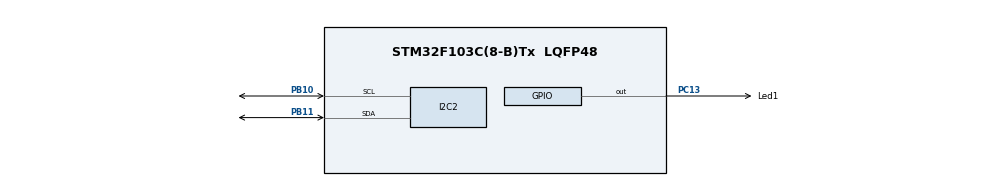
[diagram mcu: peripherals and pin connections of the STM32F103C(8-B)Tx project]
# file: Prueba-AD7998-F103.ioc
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Mcu.Family=STM32F1
Mcu.Name=STM32F103C(8-B)Tx
Mcu.Package=LQFP48
NVIC.I2C2_ER_IRQn=true\:0\:0\:false\:false\:true\:true\:true\:true
NVIC.I2C2_EV_IRQn=true\:0\:0\:false\:false\:true\:true\:true\:true
NVIC.PriorityGroup=NVIC_PRIORITYGROUP_4
PA13.Mode=Serial_Wire
PA13.Signal=SYS_JTMS-SWDIO
PA14.Mode=Serial_Wire
PA14.Signal=SYS_JTCK-SWCLK
PB10.Mode=I2C
PB10.Signal=I2C2_SCL
PB11.Mode=I2C
PB11.Signal=I2C2_SDA
PC13-TAMPER-RTC.GPIO_Label=Led1
PC13-TAMPER-RTC.Signal=GPIO_Output
PD0-OSC_IN.Mode=HSE-External-Oscillator
PD0-OSC_IN.Signal=RCC_OSC_IN
PD1-OSC_OUT.Mode=HSE-External-Oscillator
PD1-OSC_OUT.Signal=RCC_OSC_OUT
ProjectManager.HeapSize=0x200
ProjectManager.StackSize=0x400
ProjectManager.TargetToolchain=STM32CubeIDE
RCC.APB1Freq_Value=8000000
RCC.APB2Freq_Value=8000000
board=custom

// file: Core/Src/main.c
/* USER CODE BEGIN Header */
/**
  ******************************************************************************
  * @file           : main.c
  * @brief          : Main program body
  ******************************************************************************
  * @attention
  *
  * Copyright (c) 2025 STMicroelectronics.
  * All rights reserved.
  *
  * This software is licensed under terms that can be found in the LICENSE file
  * in the root directory of this software component.
  * If no LICENSE file comes with this software, it is provided AS-IS.
  *
  ******************************************************************************
  */
/* USER CODE END Header */
#include "main.h"

/* USER CODE BEGIN Includes */
#include "stdio.h"
#include "string.h"
#include "stdlib.h"

/* USER CODE END Includes */

/* USER CODE BEGIN PD */
#define AD7998_1_ADDR  (0x24 << 1)  // Dirección del primer AD7998
/* USER CODE END PD */

I2C_HandleTypeDef hi2c2;

/* USER CODE BEGIN PV */
uint8_t flag=0;
uint16_t ch_values [8]={0};
char msg[64];
/* USER CODE END PV */

void SystemClock_Config(void);
static void MX_GPIO_Init(void);
static void MX_I2C2_Init(void);

/* USER CODE BEGIN 0 */
//-------------------------------------------------------------------------------------------[Función para detectar dispositivos]

void I2C_Scan(I2C_HandleTypeDef *hi2c)
{
    for (uint8_t i = 1; i < 128; i++)
    {
        if (HAL_I2C_IsDeviceReady(hi2c, (i << 1), 1, HAL_MAX_DELAY) == HAL_OK)
        {
            sprintf(msg, "Device found at 0x%X\r\n", i);
        }
    }
}

//-------------------------------------------------------------------------------------------[Función para configurar canales]
HAL_StatusTypeDef AD7998_ConfigureAllChannels(uint8_t dev_addr)
{
    uint8_t config_payload[3];

    // 1. Primer byte: Puntero al Registro de Configuración del Ciclo de Conversión (0x02)
    config_payload[0] = 0x02;

    // 2. Segundo byte: MSB de los canales a habilitar (D15-D8). 0x0F -> 0000 1111
    config_payload[1] = 0x0F;

    // 3. Tercer byte: LSB de los canales a habilitar (D7-D0). 0xF0 -> 1111 0000
    config_payload[2] = 0xF0;

    // Juntos, 0x0FF0 habilita los canales del 1 al 8.
    // Transmitimos el paquete de 3 bytes.
    return HAL_I2C_Master_Transmit(&hi2c2, dev_addr, config_payload, 3, HAL_MAX_DELAY);
}

//-------------------------------------------------------------------------------------------[Función para leer los 8 canales de un AD7998]
uint16_t AD7998_ReadChannel(uint8_t dev_addr, uint8_t channel)
{
    HAL_StatusTypeDef ret;
    uint8_t config;
    uint8_t data[2];
    uint16_t value = 0;

    // Canal 1–8 → bits 6:4 del byte de configuración
    if (channel < 1 || channel > 8)
        return 0xFFFF; // error de canal inválido

    config = 0x80 | ((channel - 1) << 4); // bit7=1, selecciona canal.... 0x40 es para canal 7

    // Escribir el byte de configuración
    ret = HAL_I2C_Master_Transmit(&hi2c2, dev_addr, &config, 1, HAL_MAX_DELAY);
    if (ret != HAL_OK)
        return 0xFFFE; // error de transmisión

    // Pequeño retardo para que complete la conversión
    HAL_Delay(10);

    // Leer 2 bytes (MSB + LSB)
    ret = HAL_I2C_Master_Receive(&hi2c2, dev_addr, data, 2, HAL_MAX_DELAY);
    if (ret != HAL_OK)
        return 0xFFFD; // error de lectura

    // Combinar los dos bytes (12 bits válidos)
    value = ((uint16_t)data[0] << 8) | data[1];
    value = (value ) & 0x0FFF; // bits D11..D0

    return value;
}
/* USER CODE END 0 */

int main(void)
{

  /* MCU Configuration--------------------------------------------------------*/

  /* Reset of all peripherals, Initializes the Flash interface and the Systick. */
  HAL_Init();

  /* Configure the system clock */
  SystemClock_Config();

  /* Initialize all configured peripherals */
  MX_GPIO_Init();
  MX_I2C2_Init();
  /* USER CODE BEGIN 2 */
  I2C_Scan(&hi2c2);
  /* USER CODE END 2 */

  /* Infinite loop */
  /* USER CODE BEGIN WHILE */
  while (1)
  {
	  if (flag==0)
	  {
		  AD7998_ConfigureAllChannels(AD7998_1_ADDR);
		  // Bucle para leer cada uno de los 8 canales secuencialmente.
		  for (int i = 0; i < 8; i++)
		  {
			  HAL_GPIO_TogglePin(GPIOC, Led1_Pin);
			  ch_values[i] = AD7998_ReadChannel(AD7998_1_ADDR, i + 1);
			  HAL_Delay(100);
		  }
//		  flag=1;
	  }

    /* USER CODE END WHILE */

  }
}

void SystemClock_Config(void)
{
  RCC_OscInitTypeDef RCC_OscInitStruct = {0};
  RCC_ClkInitTypeDef RCC_ClkInitStruct = {0};

  /** Initializes the RCC Oscillators according to the specified parameters
  * in the RCC_OscInitTypeDef structure.
  */
  RCC_OscInitStruct.OscillatorType = RCC_OSCILLATORTYPE_HSI;
  RCC_OscInitStruct.HSIState = RCC_HSI_ON;
  RCC_OscInitStruct.HSICalibrationValue = RCC_HSICALIBRATION_DEFAULT;
  RCC_OscInitStruct.PLL.PLLState = RCC_PLL_NONE;
  if (HAL_RCC_OscConfig(&RCC_OscInitStruct) != HAL_OK)
  {
    Error_Handler();
  }

  /** Initializes the CPU, AHB and APB buses clocks
  */
  RCC_ClkInitStruct.ClockType = RCC_CLOCKTYPE_HCLK|RCC_CLOCKTYPE_SYSCLK
                              |RCC_CLOCKTYPE_PCLK1|RCC_CLOCKTYPE_PCLK2;
  RCC_ClkInitStruct.SYSCLKSource = RCC_SYSCLKSOURCE_HSI;
  RCC_ClkInitStruct.AHBCLKDivider = RCC_SYSCLK_DIV1;
  RCC_ClkInitStruct.APB1CLKDivider = RCC_HCLK_DIV1;
  RCC_ClkInitStruct.APB2CLKDivider = RCC_HCLK_DIV1;

  if (HAL_RCC_ClockConfig(&RCC_ClkInitStruct, FLASH_LATENCY_0) != HAL_OK)
  {
    Error_Handler();
  }
}

static void MX_I2C2_Init(void)
{

  hi2c2.Instance = I2C2;
  hi2c2.Init.ClockSpeed = 100000;
  hi2c2.Init.DutyCycle = I2C_DUTYCYCLE_2;
  hi2c2.Init.OwnAddress1 = 0;
  hi2c2.Init.AddressingMode = I2C_ADDRESSINGMODE_7BIT;
  hi2c2.Init.DualAddressMode = I2C_DUALADDRESS_DISABLE;
  hi2c2.Init.OwnAddress2 = 0;
  hi2c2.Init.GeneralCallMode = I2C_GENERALCALL_DISABLE;
  hi2c2.Init.NoStretchMode = I2C_NOSTRETCH_DISABLE;
  if (HAL_I2C_Init(&hi2c2) != HAL_OK)
  {
    Error_Handler();
  }

}

static void MX_GPIO_Init(void)
{
  GPIO_InitTypeDef GPIO_InitStruct = {0};

  /* GPIO Ports Clock Enable */
  __HAL_RCC_GPIOC_CLK_ENABLE();
  __HAL_RCC_GPIOD_CLK_ENABLE();
  __HAL_RCC_GPIOB_CLK_ENABLE();
  __HAL_RCC_GPIOA_CLK_ENABLE();

  /*Configure GPIO pin Output Level */
  HAL_GPIO_WritePin(Led1_GPIO_Port, Led1_Pin, GPIO_PIN_RESET);

  /*Configure GPIO pin : Led1_Pin */
  GPIO_InitStruct.Pin = Led1_Pin;
  GPIO_InitStruct.Mode = GPIO_MODE_OUTPUT_PP;
  GPIO_InitStruct.Pull = GPIO_NOPULL;
  GPIO_InitStruct.Speed = GPIO_SPEED_FREQ_LOW;
  HAL_GPIO_Init(Led1_GPIO_Port, &GPIO_InitStruct);

}

void Error_Handler(void)
{
  __disable_irq();
  while (1)
  {
  }
}
